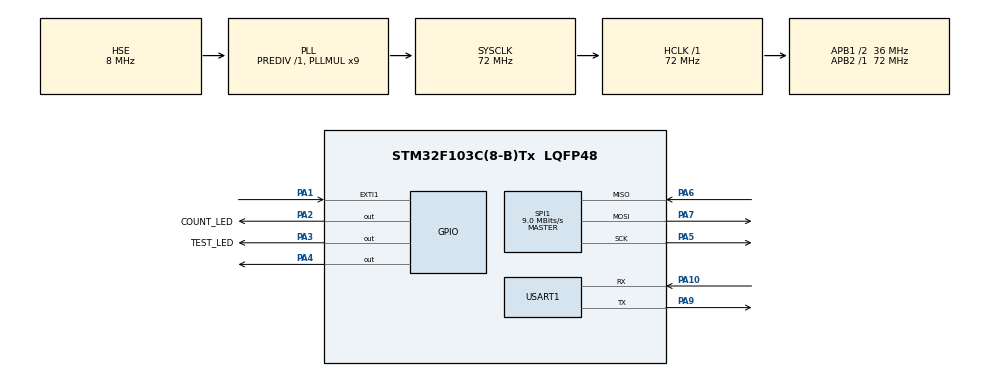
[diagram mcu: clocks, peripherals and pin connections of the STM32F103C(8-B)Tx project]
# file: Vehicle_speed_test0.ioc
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Mcu.Family=STM32F1
Mcu.Name=STM32F103C(8-B)Tx
Mcu.Package=LQFP48
NVIC.EXTI1_IRQn=true\:0\:0\:true\:false\:true\:true\:true\:true
NVIC.PriorityGroup=NVIC_PRIORITYGROUP_4
NVIC.TIM2_IRQn=true\:0\:0\:false\:false\:true\:true\:true\:true
NVIC.TIM3_IRQn=true\:0\:0\:false\:false\:true\:true\:true\:true
PA1.GPIO_ModeDefaultEXTI=GPIO_MODE_IT_FALLING
PA1.Signal=GPXTI1
PA10.Mode=Asynchronous
PA10.Signal=USART1_RX
PA13.Mode=Serial_Wire
PA13.Signal=SYS_JTMS-SWDIO
PA14.Mode=Serial_Wire
PA14.Signal=SYS_JTCK-SWCLK
PA2.GPIO_Label=COUNT_LED
PA2.Signal=GPIO_Output
PA3.GPIO_Label=TEST_LED
PA3.Signal=GPIO_Output
PA4.GPIO_PuPd=GPIO_PULLUP
PA4.Signal=GPIO_Output
PA5.Mode=Full_Duplex_Master
PA5.Signal=SPI1_SCK
PA6.Mode=Full_Duplex_Master
PA6.Signal=SPI1_MISO
PA7.Mode=Full_Duplex_Master
PA7.Signal=SPI1_MOSI
PA9.Mode=Asynchronous
PA9.Signal=USART1_TX
PD0-OSC_IN.Mode=HSE-External-Oscillator
PD0-OSC_IN.Signal=RCC_OSC_IN
PD1-OSC_OUT.Mode=HSE-External-Oscillator
PD1-OSC_OUT.Signal=RCC_OSC_OUT
ProjectManager.HeapSize=0x200
ProjectManager.StackSize=0x400
ProjectManager.TargetToolchain=STM32CubeIDE
RCC.AHBFreq_Value=72000000
RCC.APB1CLKDivider=RCC_HCLK_DIV2
RCC.APB1Freq_Value=36000000
RCC.APB1TimFreq_Value=72000000
RCC.APB2Freq_Value=72000000
RCC.APB2TimFreq_Value=72000000
RCC.HCLKFreq_Value=72000000
RCC.PLLMUL=RCC_PLL_MUL9
RCC.PLLSourceVirtual=RCC_PLLSOURCE_HSE
RCC.SYSCLKFreq_VALUE=72000000
RCC.SYSCLKSource=RCC_SYSCLKSOURCE_PLLCLK
RCC.USBFreq_Value=72000000
SPI1.BaudRatePrescaler=SPI_BAUDRATEPRESCALER_8
SPI1.CalculateBaudRate=9.0 MBits/s
SPI1.Direction=SPI_DIRECTION_2LINES
SPI1.Mode=SPI_MODE_MASTER
SPI1.VirtualType=VM_MASTER
TIM2.Period=11000
TIM2.Prescaler=7200-1
TIM3.Period=1000
TIM3.Prescaler=7200-1
USART1.VirtualMode=VM_ASYNC
VP_TIM2_VS_ClockSourceINT.Mode=Internal
VP_TIM3_VS_ClockSourceINT.Mode=Internal
VP_TIM3_VS_OPM.Mode=OPM_bit
board=custom

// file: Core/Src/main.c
/* USER CODE BEGIN Header */
/**
 ******************************************************************************
 * @file           : main.c
 * @brief          : Main program body
 ******************************************************************************
 * @attention
 *
 * Copyright (c) 2023 STMicroelectronics.
 * All rights reserved.
 *
 * This software is licensed under terms that can be found in the LICENSE file
 * in the root directory of this software component.
 * If no LICENSE file comes with this software, it is provided AS-IS.
 *
 ******************************************************************************
 */
/* USER CODE END Header */
#include "main.h"
#define HALF_OF_CIRCLE 18.84

SPI_HandleTypeDef hspi1;

TIM_HandleTypeDef htim2;
TIM_HandleTypeDef htim3;

UART_HandleTypeDef huart1;

void SystemClock_Config(void);
static void MX_GPIO_Init(void);
static void MX_USART1_UART_Init(void);
static void MX_SPI1_Init(void);
static void MX_TIM3_Init(void);
static void MX_TIM2_Init(void);
static uint8_t socNum = 0;
static uint8_t dstip[4] = {192, 168, 1, 4}; // destination ip address

static char str[50];
static float NOTMOVING = 0;
static float elapsed_time = 0;
static uint8_t lock = 0;
static uint64_t no_magnatic_hits = 0;
static float start_time = 0;
static float speed = 0.0;
// this function to unlock the lock after 0.2second
void HAL_TIM_PeriodElapsedCallback(TIM_HandleTypeDef *htim)
{
  if (htim->Instance == TIM3) // if time 0.3 make interrupt
  {

    HAL_TIM_Base_Stop_IT(&htim3);
    lock = 0;
  }
  if (htim->Instance == TIM2) // if time 1.1 make interrupt print the speed between two magnetics
  {
    if (no_magnatic_hits == 0)
    {

      sprintf(str, "%.2f", NOTMOVING);
      str[sizeof(str) - 1] = '\0';
    }
    else
    {
      sprintf(str, "%.2f", speed);
      str[sizeof(str) - 1] = '\0';
    }
    HAL_UART_Transmit(&huart1, str, sizeof(str), 100);
    no_magnatic_hits = 0;
  }
}
void HAL_GPIO_EXTI_Callback(uint16_t GPIO_Pin)
{
  // lock is used to prevent bouncing in situations where two falling edges occur in close time
  // so if two edges comes in close time after the first one lock will be one for 0.3 second->(3000*2700)/(72*10^6)

  if (GPIO_Pin == GPIO_PIN_1)
  {
    if (lock == 0)
    {
      HAL_TIM_Base_Start_IT(&htim3);
      lock = 1;
      elapsed_time = (HAL_GetTick() - start_time) / 1000.0; // calculate time between magnetics
      start_time = HAL_GetTick();                           // to save the last time
      if (elapsed_time != 0)                                // this to prevent print inf in first time
        speed = HALF_OF_CIRCLE / (elapsed_time);
      no_magnatic_hits++;
    }
  }
}

int main(void)
{

  /* MCU Configuration--------------------------------------------------------*/

  /* Reset of all peripherals, Initializes the Flash interface and the Systick. */
  HAL_Init();

  /* Configure the system clock */
  SystemClock_Config();

  /* Initialize all configured peripherals */
  MX_GPIO_Init();
  MX_USART1_UART_Init();
  MX_SPI1_Init();
  MX_TIM3_Init();
  MX_TIM2_Init();

  HAL_TIM_Base_Start_IT(&htim2);
  /* USER CODE BEGIN 2 */
  uint8_t mac[] = {0x52, 0xab, 0x3c, 0x9f, 0xd8, 0x07}; // Mac address
  uint8_t ip[] = {192, 168, 1, 170};                    // IP address
  uint8_t sn[] = {255, 255, 255, 0};                    // Subnet mask
  uint8_t gw[] = {192, 168, 1, 1};                      // Gateway address

  initializeW5500(mac, ip, sn, gw); // configures the MAC address, IP address, subnet mask and gateway of the device or node.

  while (socket(socNum, Sn_MR_UDP, 6000, 0) != socNum)
    ;
  /* USER CODE END 2 */

  /* Infinite loop */
  while (1)
  {
    Socket_sendUDP(socNum, str, dstip, 5001); // sends message to a destination ip address and port
    HAL_Delay(1000);
  }
}

void SystemClock_Config(void)
{
  RCC_OscInitTypeDef RCC_OscInitStruct = {0};
  RCC_ClkInitTypeDef RCC_ClkInitStruct = {0};

  /** Initializes the RCC Oscillators according to the specified parameters
   * in the RCC_OscInitTypeDef structure.
   */
  RCC_OscInitStruct.OscillatorType = RCC_OSCILLATORTYPE_HSE;
  RCC_OscInitStruct.HSEState = RCC_HSE_ON;
  RCC_OscInitStruct.HSEPredivValue = RCC_HSE_PREDIV_DIV1;
  RCC_OscInitStruct.HSIState = RCC_HSI_ON;
  RCC_OscInitStruct.PLL.PLLState = RCC_PLL_ON;
  RCC_OscInitStruct.PLL.PLLSource = RCC_PLLSOURCE_HSE;
  RCC_OscInitStruct.PLL.PLLMUL = RCC_PLL_MUL9;
  if (HAL_RCC_OscConfig(&RCC_OscInitStruct) != HAL_OK)
  {
    Error_Handler();
  }

  /** Initializes the CPU, AHB and APB buses clocks
   */
  RCC_ClkInitStruct.ClockType = RCC_CLOCKTYPE_HCLK | RCC_CLOCKTYPE_SYSCLK | RCC_CLOCKTYPE_PCLK1 | RCC_CLOCKTYPE_PCLK2;
  RCC_ClkInitStruct.SYSCLKSource = RCC_SYSCLKSOURCE_PLLCLK;
  RCC_ClkInitStruct.AHBCLKDivider = RCC_SYSCLK_DIV1;
  RCC_ClkInitStruct.APB1CLKDivider = RCC_HCLK_DIV2;
  RCC_ClkInitStruct.APB2CLKDivider = RCC_HCLK_DIV1;

  if (HAL_RCC_ClockConfig(&RCC_ClkInitStruct, FLASH_LATENCY_2) != HAL_OK)
  {
    Error_Handler();
  }
}

static void MX_SPI1_Init(void)
{

  /* SPI1 parameter configuration*/
  hspi1.Instance = SPI1;
  hspi1.Init.Mode = SPI_MODE_MASTER;
  hspi1.Init.Direction = SPI_DIRECTION_2LINES;
  hspi1.Init.DataSize = SPI_DATASIZE_8BIT;
  hspi1.Init.CLKPolarity = SPI_POLARITY_LOW;
  hspi1.Init.CLKPhase = SPI_PHASE_1EDGE;
  hspi1.Init.NSS = SPI_NSS_SOFT;
  hspi1.Init.BaudRatePrescaler = SPI_BAUDRATEPRESCALER_8;
  hspi1.Init.FirstBit = SPI_FIRSTBIT_MSB;
  hspi1.Init.TIMode = SPI_TIMODE_DISABLE;
  hspi1.Init.CRCCalculation = SPI_CRCCALCULATION_DISABLE;
  hspi1.Init.CRCPolynomial = 10;
  if (HAL_SPI_Init(&hspi1) != HAL_OK)
  {
    Error_Handler();
  }
}

static void MX_TIM2_Init(void)
{

  TIM_ClockConfigTypeDef sClockSourceConfig = {0};
  TIM_MasterConfigTypeDef sMasterConfig = {0};

  htim2.Instance = TIM2;
  htim2.Init.Prescaler = 7200 - 1;
  htim2.Init.CounterMode = TIM_COUNTERMODE_UP;
  htim2.Init.Period = 11000;
  htim2.Init.ClockDivision = TIM_CLOCKDIVISION_DIV1;
  htim2.Init.AutoReloadPreload = TIM_AUTORELOAD_PRELOAD_DISABLE;
  if (HAL_TIM_Base_Init(&htim2) != HAL_OK)
  {
    Error_Handler();
  }
  sClockSourceConfig.ClockSource = TIM_CLOCKSOURCE_INTERNAL;
  if (HAL_TIM_ConfigClockSource(&htim2, &sClockSourceConfig) != HAL_OK)
  {
    Error_Handler();
  }
  sMasterConfig.MasterOutputTrigger = TIM_TRGO_RESET;
  sMasterConfig.MasterSlaveMode = TIM_MASTERSLAVEMODE_DISABLE;
  if (HAL_TIMEx_MasterConfigSynchronization(&htim2, &sMasterConfig) != HAL_OK)
  {
    Error_Handler();
  }
}

static void MX_TIM3_Init(void)
{

  TIM_ClockConfigTypeDef sClockSourceConfig = {0};
  TIM_MasterConfigTypeDef sMasterConfig = {0};

  htim3.Instance = TIM3;
  htim3.Init.Prescaler = 7200 - 1;
  htim3.Init.CounterMode = TIM_COUNTERMODE_UP;
  htim3.Init.Period = 3000;
  htim3.Init.ClockDivision = TIM_CLOCKDIVISION_DIV1;
  htim3.Init.AutoReloadPreload = TIM_AUTORELOAD_PRELOAD_DISABLE;
  if (HAL_TIM_Base_Init(&htim3) != HAL_OK)
  {
    Error_Handler();
  }
  sClockSourceConfig.ClockSource = TIM_CLOCKSOURCE_INTERNAL;
  if (HAL_TIM_ConfigClockSource(&htim3, &sClockSourceConfig) != HAL_OK)
  {
    Error_Handler();
  }
  if (HAL_TIM_OnePulse_Init(&htim3, TIM_OPMODE_SINGLE) != HAL_OK)
  {
    Error_Handler();
  }
  sMasterConfig.MasterOutputTrigger = TIM_TRGO_RESET;
  sMasterConfig.MasterSlaveMode = TIM_MASTERSLAVEMODE_DISABLE;
  if (HAL_TIMEx_MasterConfigSynchronization(&htim3, &sMasterConfig) != HAL_OK)
  {
    Error_Handler();
  }
}

static void MX_USART1_UART_Init(void)
{

  huart1.Instance = USART1;
  huart1.Init.BaudRate = 115200;
  huart1.Init.WordLength = UART_WORDLENGTH_8B;
  huart1.Init.StopBits = UART_STOPBITS_1;
  huart1.Init.Parity = UART_PARITY_NONE;
  huart1.Init.Mode = UART_MODE_TX_RX;
  huart1.Init.HwFlowCtl = UART_HWCONTROL_NONE;
  huart1.Init.OverSampling = UART_OVERSAMPLING_16;
  if (HAL_UART_Init(&huart1) != HAL_OK)
  {
    Error_Handler();
  }
}

static void MX_GPIO_Init(void)
{
  GPIO_InitTypeDef GPIO_InitStruct = {0};

  /* GPIO Ports Clock Enable */
  __HAL_RCC_GPIOD_CLK_ENABLE();
  __HAL_RCC_GPIOA_CLK_ENABLE();

  /*Configure GPIO pin Output Level */
  HAL_GPIO_WritePin(GPIOA, COUNT_LED_Pin | TEST_LED_Pin | GPIO_PIN_4, GPIO_PIN_RESET);

  /*Configure GPIO pin : PA1 */
  GPIO_InitStruct.Pin = GPIO_PIN_1;
  GPIO_InitStruct.Mode = GPIO_MODE_IT_FALLING;
  GPIO_InitStruct.Pull = GPIO_NOPULL;
  HAL_GPIO_Init(GPIOA, &GPIO_InitStruct);

  /*Configure GPIO pins : COUNT_LED_Pin TEST_LED_Pin */
  GPIO_InitStruct.Pin = COUNT_LED_Pin | TEST_LED_Pin;
  GPIO_InitStruct.Mode = GPIO_MODE_OUTPUT_PP;
  GPIO_InitStruct.Pull = GPIO_NOPULL;
  GPIO_InitStruct.Speed = GPIO_SPEED_FREQ_LOW;
  HAL_GPIO_Init(GPIOA, &GPIO_InitStruct);

  /*Configure GPIO pin : PA4 */
  GPIO_InitStruct.Pin = GPIO_PIN_4;
  GPIO_InitStruct.Mode = GPIO_MODE_OUTPUT_PP;
  GPIO_InitStruct.Pull = GPIO_PULLUP;
  GPIO_InitStruct.Speed = GPIO_SPEED_FREQ_LOW;
  HAL_GPIO_Init(GPIOA, &GPIO_InitStruct);

  /* EXTI interrupt init*/
  HAL_NVIC_SetPriority(EXTI1_IRQn, 0, 0);
  HAL_NVIC_EnableIRQ(EXTI1_IRQn);
}

void Error_Handler(void)
{
  __disable_irq();
  while (1)
  {
  }
}
